# R7FA2A2AD register map
Vendor: Renesas Electronics Corporation; Series: RA2A2; File version: 1.20.02
CPU: CM23 r1p0, little endian, MPU, no FPU, VTOR, 2 interrupt priority bits, 32 interrupts
Registers are 8-bit, read-write, reset 0x0 unless marked. A register's access mark holds for its fields unless they carry their own. Offsets are from the block's base; [hi:lo] are bit positions; {n}, {i} and the like mark numbered series.

## GPT_OPS — Output Phase Switching Controller
Base 0x40078FF0
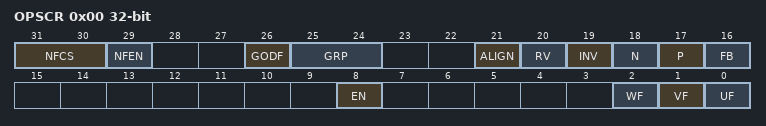
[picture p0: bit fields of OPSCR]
0x00 OPSCR 32-bit — Output Phase Switching Control Register
  [31:30] NFCS — External Input Noise Filter Clock Selection
  [29] NFEN — External Input Noise Filter Enable
  [26] GODF — Group Output Disable Function
  [25:24] GRP — Output Disabled Source Selection
  [21] ALIGN — Input Phase Alignment
  [20] RV — Output Phase Rotation Direction Reversal Control
  [19] INV — Output Phase Invert Control
  [18] N — Negative,Phase Output (N) Control
  [17] P — Positive,Phase Output (P) Control
  [16] FB — External Feedback Signal Enable
  [8] EN — Output Phase Enable
  [2] WF
  [1] VF
  [0] UF

## SLCDC — Segment LCD Controller
Base 0x40082000
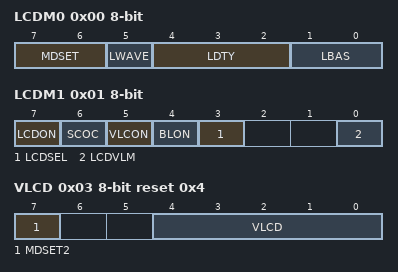
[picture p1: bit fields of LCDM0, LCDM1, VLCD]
0x00 LCDM0 — LCD Mode Register 0
  [7:6] MDSET — LCD Drive Voltage Generator Select
  [5] LWAVE — LCD Display Waveform Select
  [4:2] LDTY — Time Slice of LCD Display Select
  [1:0] LBAS — LCD Display Bias Method Select
0x01 LCDM1 — LCD Mode Register 1
  [7] LCDON — LCD Display Enable/Disable
  [6] SCOC — LCD Display Enable/Disable
  [5] VLCON — Voltage Boost Circuit or Capacitor Split Circuit Operation Enable/Disable
  [4] BLON — Alternately Display A,pattern and B,pattern Area Data (blinking display) Control
  [3] LCDSEL — Display Area Data Selection
  [0] LCDVLM — Voltage Boosting Pin Initial Value Switching Control
0x02 LCDC0 — LCD Clock Control Register 0
  [5:0] LCDC0 — LCD Clock (LCDCL) Setting
0x03 VLCD reset 0x4 — LCD Boost Level Control Register
  [7] MDSET2 — Reference Voltage Selection
  [4:0] VLCD — Reference Voltage Select (Contrast Adjustment)
{0x100+i} SEG[{i}] (i=0..44) — LCD Display Data Register {i}

## AGTW0 — Low Power Asynchronous General Purpose Timer 0
Base 0x40084000
Same registers: AGTW1 0x40084100
0x00 AGT 32-bit reset 0xFFFFFFFF — AGT Counter Register
0x04 AGTCMA 32-bit reset 0xFFFFFFFF — AGT Compare Match A Register
0x08 AGTCMB 32-bit reset 0xFFFFFFFF — AGT Compare Match B Register
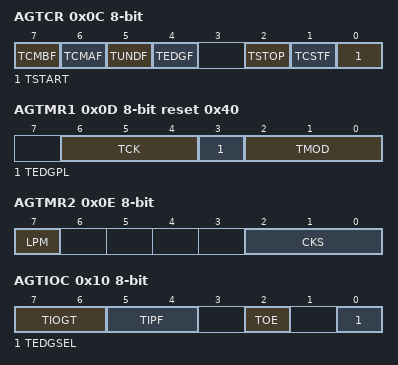
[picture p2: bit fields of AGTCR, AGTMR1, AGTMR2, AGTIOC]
0x0C AGTCR — AGT Control Register
  [7] TCMBF — Compare Match B Flag
  [6] TCMAF — Compare Match A Flag
  [5] TUNDF — Underflow Flag
  [4] TEDGF — Active Edge Judgment Flag
  [2] TSTOP wo — AGT Count Forced Stop
  [1] TCSTF ro — AGT Count Status Flag
  [0] TSTART — AGT Count Start
0x0D AGTMR1 reset 0x40 — AGT Mode Register 1
  [6:4] TCK — Count Source
  [3] TEDGPL — Edge Polarity
  [2:0] TMOD — Operating Mode
0x0E AGTMR2 — AGT Mode Register 2
  [7] LPM — Low Power Mode
  [2:0] CKS — AGTLCLK or AGTSCLK Count Source Clock Frequency Division Ratio
0x0F AGTIOSEL — AGT Pin Select Register
  [4] TIES — AGTWIOn Pin Input Enable
0x10 AGTIOC — AGT I/O Control Register
  [7:6] TIOGT — Count Control
  [5:4] TIPF — Input Filter
  [2] TOE — AGTWOn pin Output Enable
  [0] TEDGSEL — I/O Polarity Switch
0x11 AGTISR — AGT Event Pin Select Register
  [2] EEPS — AGTWEEn Polarity Selection
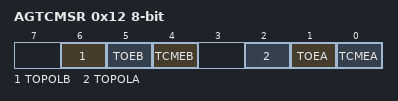
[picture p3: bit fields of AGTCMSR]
0x12 AGTCMSR — AGT Compare Match Function Select Register
  [6] TOPOLB — AGTWOBn Pin Polarity Select
  [5] TOEB — AGTWOBn Pin Output Enable
  [4] TCMEB — AGT Compare Match B Register Enable
  [2] TOPOLA — AGTWOAn Pin Polarity Select
  [1] TOEA — AGTWOAn Pin Output Enable
  [0] TCMEA — AGT Compare Match A Register Enable

## AGT0 — Low Power Asynchronous General Purpose Timer 0
Base 0x40084200
Same registers: AGT1 0x40084300, AGT2 0x40084400, AGT3 0x40084500, AGT4 0x40084600, AGT5 0x40084700, AGT6 0x40084800, AGT7 0x40084900
0x00 AGT 16-bit reset 0xFFFF — AGT Counter Register
0x02 AGTCMA 16-bit reset 0xFFFF — AGT Compare Match A Register
0x04 AGTCMB 16-bit reset 0xFFFF — AGT Compare Match B Register
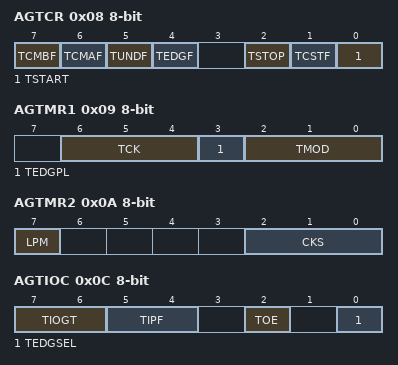
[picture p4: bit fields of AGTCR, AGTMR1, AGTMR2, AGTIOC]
0x08 AGTCR — AGT Control Register
  [7] TCMBF — Compare Match B Flag
  [6] TCMAF — Compare Match A Flag
  [5] TUNDF — Underflow Flag
  [4] TEDGF — Active Edge Judgment Flag
  [2] TSTOP wo — AGT Count Forced Stop
  [1] TCSTF ro — AGT Count Status Flag
  [0] TSTART — AGT Count Start
0x09 AGTMR1 — AGT Mode Register 1
  [6:4] TCK — Count Source
  [3] TEDGPL — Edge Polarity
  [2:0] TMOD — Operating Mode
0x0A AGTMR2 — AGT Mode Register 2
  [7] LPM — Low Power Mode
  [2:0] CKS — AGTLCLK or AGTSCLK Count Source Clock Frequency Division Ratio
0x0C AGTIOC — AGT I/O Control Register
  [7:6] TIOGT — Count Control
  [5:4] TIPF — Input Filter
  [2] TOE — AGTOn pin Output Enable
  [0] TEDGSEL — I/O Polarity Switch
0x0D AGTISR — AGT Event Pin Select Register
  [2] EEPS — AGTEEn Polarity Selection
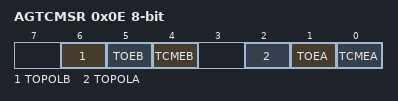
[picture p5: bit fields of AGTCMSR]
0x0E AGTCMSR — AGT Compare Match Function Select Register
  [6] TOPOLB — AGTOBn Pin Polarity Select
  [5] TOEB — AGTOBn Pin Output Enable
  [4] TCMEB — AGT Compare Match B Register Enable
  [2] TOPOLA — AGTOAn Pin Polarity Select
  [1] TOEA — AGTOAn Pin Output Enable
  [0] TCMEA — AGT Compare Match A Register Enable
0x0F AGTIOSEL — AGT Pin Select Register
  [4] TIES — AGTIOn Pin Input Enable
